# nrf5340_network register map
Vendor: Nordic Semiconductor; Series: nrf53; File version: 1
CPU: CM33 r0p4, little endian, MPU, no FPU, 3 interrupt priority bits, 30 interrupts
Registers are 32-bit, read-write, reset 0x0 unless marked. A register's access mark holds for its fields unless they carry their own. Offsets are from the block's base; [hi:lo] are bit positions; lines under a group give offsets from that group; 'fields as' and 'values as' point back to an identical list.

## CTRLAP_NS — Control access port
Base 0x41006000
0x400 MAILBOX group — Unspecified
  0x00 RXDATA ro — Data sent from the debugger to the CPU.
    [31:0] RXDATA — Data received from debugger
  0x04 RXSTATUS ro — This register shows a status that indicates if data sent from the debugger to the CPU has been read.
    [0] RXSTATUS — Status of data in register RXDATA
      0=No data pending in register RXDATA; 1=Data pending in register RXDATA
  0x80 TXDATA — Data sent from the CPU to the debugger.
    [31:0] TXDATA — Data sent to debugger
  0x84 TXSTATUS ro — This register shows a status that indicates if the data sent from the CPU to the debugger has been read.
    [0] TXSTATUS — Status of data in register TXDATA
      0=No data pending in register TXDATA; 1=Data pending in register TXDATA
0x500 ERASEPROTECT group — Unspecified
  0x00 LOCK rw-once — This register locks the ERASEPROTECT.DISABLE register from being written until next reset.
    [0] LOCK — Lock ERASEPROTECT.DISABLE register from being written until next reset
      0=Unlocked (Register ERASEPROTECT.DISABLE is writeable); 1=Locked (Register ERASEPROTECT.DISABLE is read-only)
  0x04 DISABLE rw-once — This register disables the ERASEPROTECT register and performs an ERASEALL operation.
    [31:0] KEY — The ERASEALL sequence is initiated if the value of the KEY fields are non-zero and the KEY fields match on both the CPU and debugger sides.
0x540 APPROTECT group — Unspecified
  0x00 LOCK rw-once — This register locks the APPROTECT.DISABLE register from being written to until next reset.
    [0] LOCK — Lock the APPROTECT.DISABLE register from being written to until next reset
      0=Unlocked (Register APPROTECT.DISABLE is writeable); 1=Locked (Register APPROTECT.DISABLE is read-only)
  0x04 DISABLE — This register disables the APPROTECT register and enables debug access to non-secure mode.
    [31:0] KEY — If the value of the KEY field is non-zero, and the KEY fields match on both the CPU and debugger sides, disable APPROTECT and enable debug access to non-secure mode until the next pin reset, brown-out reset, power-on reset, or watchog timer reset. After reset the debugger side register has a fixed KEY value. To enable debug access, both CTRL-AP and UICR.APPROTECT protection needs to be disabled.
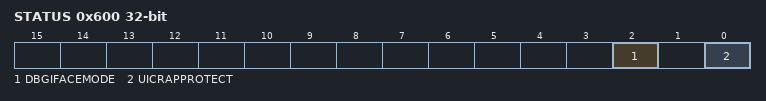
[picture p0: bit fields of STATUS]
0x600 STATUS ro — Status bits for CTRL-AP peripheral.
  [2] DBGIFACEMODE — Status bit for device debug interface mode
    0=Disabled (No debugger attached); 1=Enabled (Debugger is attached and device is in debug interface mode)
  [0] UICRAPPROTECT — Status bit for UICR part of access port protection at last reset.
    0=Enabled (APPROTECT was enabled in UICR); 1=Disabled (APPROTECT wasdisabled in UICR)

## RNG_NS — Random Number Generator
Base 0x41009000
0x00 TASKS_START wo — Task starting the random number generator
  [0] TASKS_START
    1=Trigger task
0x04 TASKS_STOP wo — Task stopping the random number generator
  [0] TASKS_STOP
    1=Trigger task
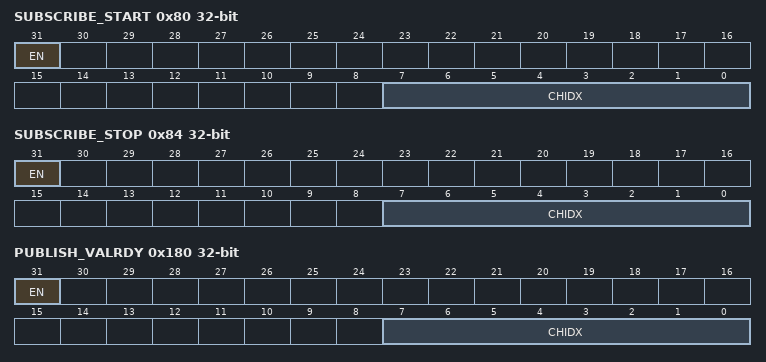
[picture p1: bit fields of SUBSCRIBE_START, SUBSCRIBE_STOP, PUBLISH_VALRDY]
0x80 SUBSCRIBE_START — Subscribe configuration for task START
  [31] EN
    0=Disabled (Disable subscription); 1=Enabled (Enable subscription)
  [7:0] CHIDX — DPPI channel that task START will subscribe to
0x84 SUBSCRIBE_STOP — Subscribe configuration for task STOP
  [31] EN
    values as SUBSCRIBE_START.EN
  [7:0] CHIDX — DPPI channel that task STOP will subscribe to
0x100 EVENTS_VALRDY — Event being generated for every new random number written to the VALUE register
  [0] EVENTS_VALRDY
    0=NotGenerated (Event not generated); 1=Generated (Event generated)
0x180 PUBLISH_VALRDY — Publish configuration for event VALRDY
  [31] EN
    0=Disabled (Disable publishing); 1=Enabled (Enable publishing)
  [7:0] CHIDX — DPPI channel that event VALRDY will publish to.
0x200 SHORTS — Shortcuts between local events and tasks
  [0] VALRDY_STOP — Shortcut between event VALRDY and task STOP
    0=Disabled (Disable shortcut); 1=Enabled (Enable shortcut)
0x304 INTENSET — Enable interrupt
  [0] VALRDY — Write '1' to enable interrupt for event VALRDY
    on read: 0=Disabled (Read: Disabled); 1=Enabled (Read: Enabled) | on write: 1=Set (Enable)
0x308 INTENCLR — Disable interrupt
  [0] VALRDY — Write '1' to disable interrupt for event VALRDY
    on read: 0=Disabled (Read: Disabled); 1=Enabled (Read: Enabled) | on write: 1=Clear (Disable)
0x504 CONFIG — Configuration register
  [0] DERCEN — Bias correction
    0=Disabled; 1=Enabled
0x508 VALUE ro — Output random number
  [7:0] VALUE — Generated random number

## Notices in the file
Copyright (c) 2010 - 2021, Nordic Semiconductor ASA All rights reserved.
SPDX-License-Identifier: BSD-3-Clause
Redistribution and use in source and binary forms, with or without
modification, are permitted provided that the following conditions are met:
1. Redistributions of source code must retain the above copyright notice, this
list of conditions and the following disclaimer.
2. Redistributions in binary form must reproduce the above copyright
notice, this list of conditions and the following disclaimer in the
documentation and/or other materials provided with the distribution.
3. Neither the name of Nordic Semiconductor ASA nor the names of its
contributors may be used to endorse or promote products derived from this
software without specific prior written permission.
THIS SOFTWARE IS PROVIDED BY THE COPYRIGHT HOLDERS AND CONTRIBUTORS "AS IS"
AND ANY EXPRESS OR IMPLIED WARRANTIES, INCLUDING, BUT NOT LIMITED TO, THE
IMPLIED WARRANTIES OF MERCHANTABILITY, AND FITNESS FOR A PARTICULAR PURPOSE
ARE DISCLAIMED. IN NO EVENT SHALL NORDIC SEMICONDUCTOR ASA OR CONTRIBUTORS BE
LIABLE FOR ANY DIRECT, INDIRECT, INCIDENTAL, SPECIAL, EXEMPLARY, OR
CONSEQUENTIAL DAMAGES (INCLUDING, BUT NOT LIMITED TO, PROCUREMENT OF
SUBSTITUTE GOODS OR SERVICES; LOSS OF USE, DATA, OR PROFITS; OR BUSINESS
INTERRUPTION) HOWEVER CAUSED AND ON ANY THEORY OF LIABILITY, WHETHER IN
CONTRACT, STRICT LIABILITY, OR TORT (INCLUDING NEGLIGENCE OR OTHERWISE)
ARISING IN ANY WAY OUT OF THE USE OF THIS SOFTWARE, EVEN IF ADVISED OF THE
POSSIBILITY OF SUCH DAMAGE.
